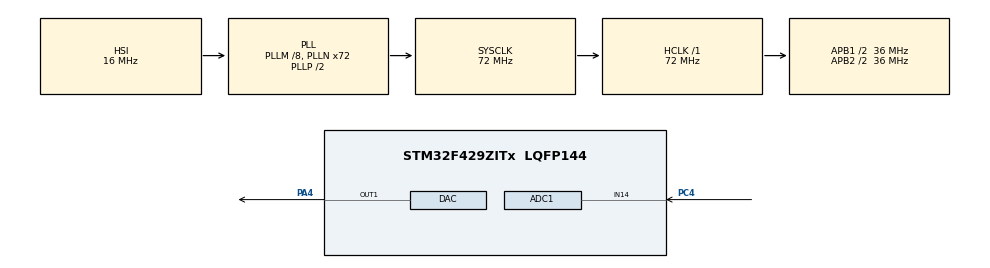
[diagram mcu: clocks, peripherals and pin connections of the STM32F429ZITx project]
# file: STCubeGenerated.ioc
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ADC1.Channel-0\#ChannelRegularConversion=ADC_CHANNEL_14
ADC1.DMAContinuousRequests=ENABLE
ADC1.ExternalTrigConv=ADC_EXTERNALTRIGCONV_T2_TRGO
ADC1.NbrOfConversionFlag=1
ADC1.Rank-0\#ChannelRegularConversion=1
ADC1.SamplingTime-0\#ChannelRegularConversion=ADC_SAMPLETIME_3CYCLES
ADC1.master=1
DAC.DAC_OutputBuffer=DAC_OUTPUTBUFFER_DISABLE
DAC.DAC_Trigger=DAC_TRIGGER_T2_TRGO
Dma.ADC1.0.Direction=DMA_PERIPH_TO_MEMORY
Dma.ADC1.0.FIFOMode=DMA_FIFOMODE_DISABLE
Dma.ADC1.0.Instance=DMA2_Stream0
Dma.ADC1.0.MemDataAlignment=DMA_MDATAALIGN_WORD
Dma.ADC1.0.MemInc=DMA_MINC_ENABLE
Dma.ADC1.0.Mode=DMA_CIRCULAR
Dma.ADC1.0.PeriphDataAlignment=DMA_PDATAALIGN_WORD
Dma.ADC1.0.PeriphInc=DMA_PINC_DISABLE
Dma.ADC1.0.Priority=DMA_PRIORITY_HIGH
Dma.DAC1.1.Direction=DMA_MEMORY_TO_PERIPH
Dma.DAC1.1.FIFOMode=DMA_FIFOMODE_DISABLE
Dma.DAC1.1.Instance=DMA1_Stream5
Dma.DAC1.1.MemDataAlignment=DMA_MDATAALIGN_WORD
Dma.DAC1.1.MemInc=DMA_MINC_ENABLE
Dma.DAC1.1.Mode=DMA_CIRCULAR
Dma.DAC1.1.PeriphDataAlignment=DMA_PDATAALIGN_WORD
Dma.DAC1.1.PeriphInc=DMA_PINC_DISABLE
Dma.DAC1.1.Priority=DMA_PRIORITY_LOW
Dma.Request0=ADC1
Dma.Request1=DAC1
Mcu.Family=STM32F4
Mcu.Name=STM32F429ZITx
Mcu.Package=LQFP144
NVIC.DMA1_Stream5_IRQn=true\:0\:0\:false\:false\:true\:false\:true
NVIC.DMA2_Stream0_IRQn=true\:0\:0\:false\:false\:true\:false\:true
NVIC.PriorityGroup=NVIC_PRIORITYGROUP_4
PA4.Signal=COMP_DAC1_group
PC4.Signal=ADCx_IN14
ProjectManager.HeapSize=0x200
ProjectManager.StackSize=0x400
ProjectManager.TargetToolchain=MDK-ARM V5
RCC.48MHZClocksFreq_Value=36000000
RCC.AHBFreq_Value=72000000
RCC.APB1CLKDivider=RCC_HCLK_DIV2
RCC.APB1Freq_Value=36000000
RCC.APB1TimFreq_Value=72000000
RCC.APB2CLKDivider=RCC_HCLK_DIV2
RCC.APB2Freq_Value=36000000
RCC.APB2TimFreq_Value=72000000
RCC.CortexFreq_Value=72000000
RCC.HCLKFreq_Value=72000000
RCC.HSE_VALUE=25000000
RCC.HSI_VALUE=16000000
RCC.LSE_VALUE=32768
RCC.PLLM=8
RCC.PLLN=72
RCC.SYSCLKFreq_VALUE=72000000
RCC.SYSCLKSource=RCC_SYSCLKSOURCE_PLLCLK
RCC.VCOOutputFreq_Value=144000000
SH.ADCx_IN14.0=ADC1_IN14,IN14
SH.COMP_DAC1_group.0=DAC_OUT1,DAC_OUT1
TIM2.AutoReloadPreload=TIM_AUTORELOAD_PRELOAD_ENABLE
TIM2.Period=749
TIM2.TIM_MasterOutputTrigger=TIM_TRGO_UPDATE
VP_TIM2_VS_ClockSourceINT.Mode=Internal
board=custom

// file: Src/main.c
/* USER CODE BEGIN Header */
/**
  ******************************************************************************
  * @file           : main.c
  * @brief          : Main program body
  ******************************************************************************
  * @attention
  *
  * <h2><center>&copy; Copyright (c) 2019 STMicroelectronics.
  * All rights reserved.</center></h2>
  *
  * This software component is licensed by ST under BSD 3-Clause license,
  * the "License"; You may not use this file except in compliance with the
  * License. You may obtain a copy of the License at:
  *                        opensource.org/licenses/BSD-3-Clause
  *
  ******************************************************************************
  */
/* USER CODE END Header */

#include "main.h"
#include "adc.h"
#include "dac.h"
#include "dma.h"
#include "tim.h"
#include "gpio.h"

/* USER CODE BEGIN Includes */
#include "fir.h"
/* USER CODE END Includes */

void SystemClock_Config(void);
/* USER CODE BEGIN PFP */
void HAL_ADC_ConvHalfCpltCallback(ADC_HandleTypeDef* hadc);
void HAL_ADC_ConvCpltCallback(ADC_HandleTypeDef* hadc);
void processDSP(void);
/* USER CODE END PFP */

/* USER CODE BEGIN 0 */

uint32_t freq;
uint32_t adcData[BUFFER_SIZE], dacData[BUFFER_SIZE];
float32_t dacFloatBuffer[BUFFER_SIZE];
float32_t adcFloatBuffer[BUFFER_SIZE];
uint32_t *adcBufferPtr;
uint32_t *dacBufferPtr;

void runnit(void) {

	int i = 0;
	/*
	for (i = 0; i < DATA_SIZE; i++) {
		adcFloatBuffer[i] = ((float)adcBufferPtr[i]) - 2048;
	}

	fir_lp_filter((float32_t *)adcFloatBuffer, (float32_t *)dacFloatBuffer, DATA_SIZE);
	//fir_hp_filter((float32_t *)adcFloatBuffer, (float32_t *)dacFloatBuffer, DATA_SIZE);
	//fir_notch_filter((float32_t *)adcFloatBuffer, (float32_t *)dacFloatBuffer, DATA_SIZE);
	//fir_pass_filter((float32_t *)adcFloatBuffer, (float32_t *)dacFloatBuffer, DATA_SIZE);
	for (i = 0; i < DATA_SIZE; i++) {
		dacBufferPtr[i] = (uint32_t)(dacFloatBuffer[i] + 2048);
	}
	*/

	for (i = 0; i < DATA_SIZE; i++) {
		dacBufferPtr[i] = adcBufferPtr[i];
	}

}

/**
  * @brief  Regular conversion half DMA transfer callback in non blocking mode
  * @param  hadc pointer to a ADC_HandleTypeDef structure that contains
  *         the configuration information for the specified ADC.
  * @retval None
  */
void HAL_ADC_ConvHalfCpltCallback(ADC_HandleTypeDef* hadc)
{
  adcBufferPtr = &adcData[0];
	dacBufferPtr = &dacData[DATA_SIZE];
}

/**
  * @brief  Regular conversion complete callback in non blocking mode
  * @param  hadc pointer to a ADC_HandleTypeDef structure that contains
  *         the configuration information for the specified ADC.
  * @retval None
  */
void HAL_ADC_ConvCpltCallback(ADC_HandleTypeDef* hadc)
{
  adcBufferPtr = &adcData[DATA_SIZE];
	dacBufferPtr = &dacData[0];
}

/* USER CODE END 0 */

int main(void)
{

  /* MCU Configuration--------------------------------------------------------*/

  /* Reset of all peripherals, Initializes the Flash interface and the Systick. */
  HAL_Init();

  /* Configure the system clock */
  SystemClock_Config();

  /* Initialize all configured peripherals */
  MX_GPIO_Init();
  MX_DMA_Init();
  MX_ADC1_Init();
  MX_TIM2_Init();
  MX_DAC_Init();
  /* USER CODE BEGIN 2 */

	fir_init();

	HAL_TIM_Base_Start(&htim2);
	HAL_ADC_Start_DMA(&hadc1,(uint32_t *) adcData, BUFFER_SIZE);
	HAL_DAC_Start_DMA(&hdac, DAC_CHANNEL_1, (uint32_t *) dacData, BUFFER_SIZE, DAC_ALIGN_12B_R);
	freq = HAL_RCC_GetPCLK1Freq();
  /* USER CODE END 2 */

  /* Infinite loop */
  /* USER CODE BEGIN WHILE */
  while (1)
  {
		runnit();
    /* USER CODE END WHILE */

  }
}

void SystemClock_Config(void)
{
  RCC_OscInitTypeDef RCC_OscInitStruct = {0};
  RCC_ClkInitTypeDef RCC_ClkInitStruct = {0};

  /** Configure the main internal regulator output voltage
  */
  __HAL_RCC_PWR_CLK_ENABLE();
  __HAL_PWR_VOLTAGESCALING_CONFIG(PWR_REGULATOR_VOLTAGE_SCALE3);
  /** Initializes the CPU, AHB and APB busses clocks
  */
  RCC_OscInitStruct.OscillatorType = RCC_OSCILLATORTYPE_HSI;
  RCC_OscInitStruct.HSIState = RCC_HSI_ON;
  RCC_OscInitStruct.HSICalibrationValue = RCC_HSICALIBRATION_DEFAULT;
  RCC_OscInitStruct.PLL.PLLState = RCC_PLL_ON;
  RCC_OscInitStruct.PLL.PLLSource = RCC_PLLSOURCE_HSI;
  RCC_OscInitStruct.PLL.PLLM = 8;
  RCC_OscInitStruct.PLL.PLLN = 72;
  RCC_OscInitStruct.PLL.PLLP = RCC_PLLP_DIV2;
  RCC_OscInitStruct.PLL.PLLQ = 4;
  if (HAL_RCC_OscConfig(&RCC_OscInitStruct) != HAL_OK)
  {
    Error_Handler();
  }
  /** Initializes the CPU, AHB and APB busses clocks
  */
  RCC_ClkInitStruct.ClockType = RCC_CLOCKTYPE_HCLK|RCC_CLOCKTYPE_SYSCLK
                              |RCC_CLOCKTYPE_PCLK1|RCC_CLOCKTYPE_PCLK2;
  RCC_ClkInitStruct.SYSCLKSource = RCC_SYSCLKSOURCE_PLLCLK;
  RCC_ClkInitStruct.AHBCLKDivider = RCC_SYSCLK_DIV1;
  RCC_ClkInitStruct.APB1CLKDivider = RCC_HCLK_DIV2;
  RCC_ClkInitStruct.APB2CLKDivider = RCC_HCLK_DIV2;

  if (HAL_RCC_ClockConfig(&RCC_ClkInitStruct, FLASH_LATENCY_2) != HAL_OK)
  {
    Error_Handler();
  }
}

void Error_Handler(void)
{
}

/************************ (C) COPYRIGHT STMicroelectronics *****END OF FILE****/
